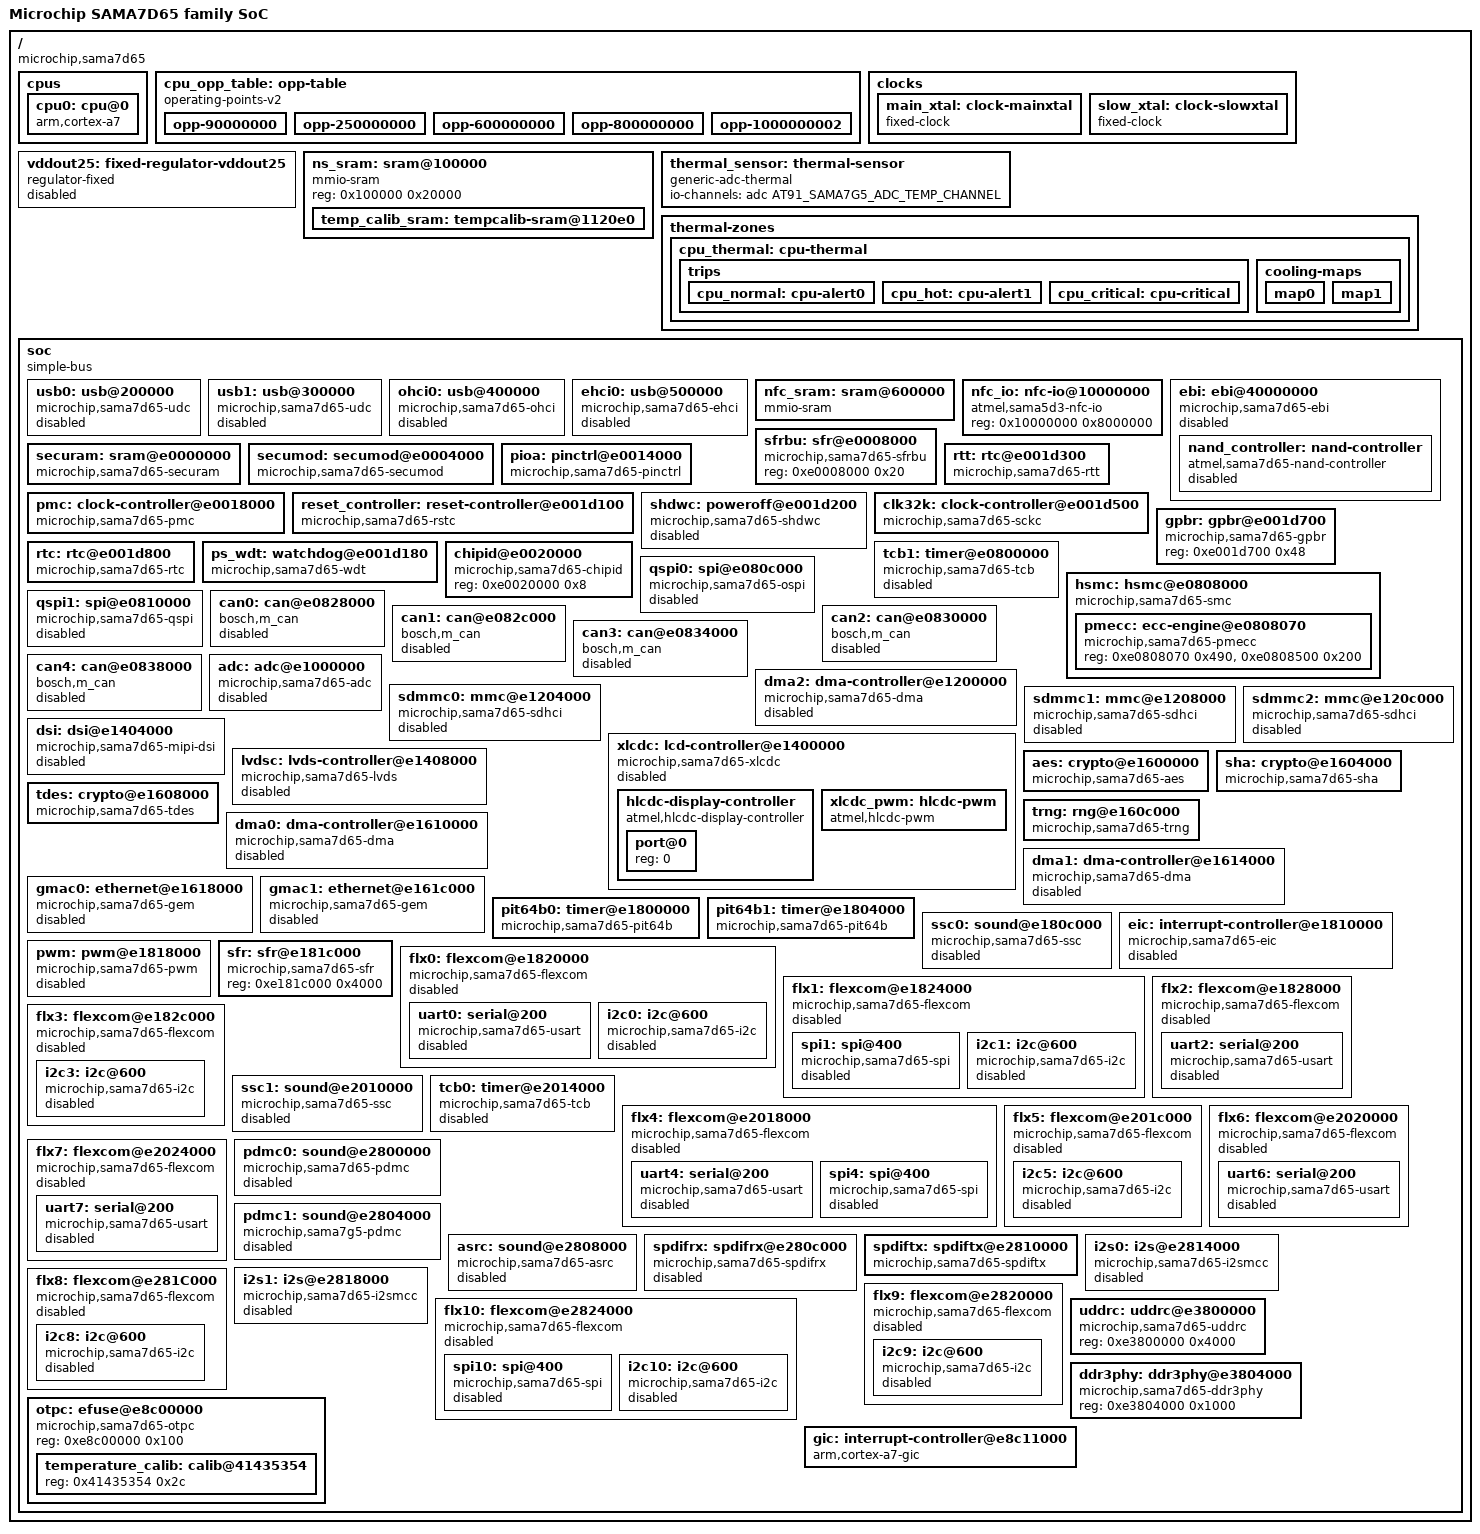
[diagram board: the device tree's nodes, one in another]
// SPDX-License-Identifier: (GPL-2.0+ OR MIT)
/*
 *  sama7d65.dtsi - Device Tree Include file for SAMA7D65 SoC
 *
 *  Copyright (C) 2024 Microchip Technology Inc. and its subsidiaries
 *
 *  Author: Ryan Wanner <Ryan.Wanner@microchip.com>
 *
 */

#include <dt-bindings/clock/at91.h>
#include <dt-bindings/dma/at91.h>
#include <dt-bindings/gpio/gpio.h>
#include <dt-bindings/iio/adc/at91-sama5d2_adc.h>
#include <dt-bindings/interrupt-controller/arm-gic.h>
#include <dt-bindings/interrupt-controller/irq.h>
#include <dt-bindings/mfd/at91-usart.h>
#include <dt-bindings/nvmem/microchip,sama7g5-otpc.h>
#include <dt-bindings/thermal/thermal.h>
#include <dt-bindings/reset/sama7g5-reset.h>

/ {
	model = "Microchip SAMA7D65 family SoC";
	compatible = "microchip,sama7d65";
	#address-cells = <1>;
	#size-cells = <1>;
	interrupt-parent = <&gic>;

	cpus {
		#address-cells = <1>;
		#size-cells = <0>;

		cpu0: cpu@0 {
			compatible = "arm,cortex-a7";
			reg = <0x0>;
			device_type = "cpu";
			clocks = <&pmc PMC_TYPE_CORE PMC_CPUPLL>;
			clock-names = "cpu";
			operating-points-v2 = <&cpu_opp_table>;
			#cooling-cells = <2>; /* min followed by max */
		};
	};

	cpu_opp_table: opp-table {
		compatible = "operating-points-v2";

		opp-90000000 {
			opp-hz = /bits/ 64 <90000000>;
			opp-microvolt = <1050000 1050000 1225000>;
			clock-latency-ns = <320000>;
		};

		opp-250000000 {
			opp-hz = /bits/ 64 <250000000>;
			opp-microvolt = <1050000 1050000 1225000>;
			clock-latency-ns = <320000>;
		};

		opp-600000000 {
			opp-hz = /bits/ 64 <600000000>;
			opp-microvolt = <1050000 1050000 1225000>;
			clock-latency-ns = <320000>;
			opp-suspend;
		};

		opp-800000000 {
			opp-hz = /bits/ 64 <800000000>;
			opp-microvolt = <1150000 1125000 1225000>;
			clock-latency-ns = <320000>;
		};

		opp-1000000002 {
			opp-hz = /bits/ 64 <1000000002>;
			opp-microvolt = <1250000 1225000 1300000>;
			clock-latency-ns = <320000>;
		};
	};

	clocks {
		main_xtal: clock-mainxtal {
			compatible = "fixed-clock";
			#clock-cells = <0>;
		};

		slow_xtal: clock-slowxtal {
			compatible = "fixed-clock";
			#clock-cells = <0>;
		};
	};

	vddout25: fixed-regulator-vddout25 {
		compatible = "regulator-fixed";

		regulator-name = "VDDOUT25";
		regulator-min-microvolt = <2500000>;
		regulator-max-microvolt = <2500000>;
		regulator-boot-on;
		status = "disabled";
	};

	ns_sram: sram@100000 {
		compatible = "mmio-sram";
		#address-cells = <1>;
		#size-cells = <1>;
		reg = <0x100000 0x20000>;
		ranges;

		temp_calib_sram: tempcalib-sram@1120e0 {
			reg = <0x1120e0 0x40>;
			pool;
		};
	};

	thermal_sensor: thermal-sensor {
		compatible = "generic-adc-thermal";
		#thermal-sensor-cells = <0>;
		io-channels = <&adc AT91_SAMA7G5_ADC_TEMP_CHANNEL>;
		io-channel-names = "sensor-channel";
	};

	thermal-zones {
		cpu_thermal: cpu-thermal {
			polling-delay-passive = <1000>;
			polling-delay = <5000>;
			thermal-sensors = <&thermal_sensor>;

			trips {
				cpu_normal: cpu-alert0 {
					temperature = <90000>;
					hysteresis = <0>;
					type = "passive";
				};

				cpu_hot: cpu-alert1 {
					temperature = <95000>;
					hysteresis = <0>;
					type = "passive";
				};

				cpu_critical: cpu-critical {
					temperature = <100000>;
					hysteresis = <0>;
					type = "critical";
				};
			};

			cooling-maps {
				map0 {
					trip = <&cpu_normal>;
					cooling-device = <&cpu0 THERMAL_NO_LIMIT THERMAL_NO_LIMIT>;
				};

				map1 {
					trip = <&cpu_hot>;
					cooling-device = <&cpu0 THERMAL_NO_LIMIT THERMAL_NO_LIMIT>;
				};
			};
		};
	};

	soc {
		compatible = "simple-bus";
		ranges;
		#address-cells = <1>;
		#size-cells = <1>;

		usb0: usb@200000 {		// AT91 USB device controller on port A
			compatible = "microchip,sama7d65-udc", "microchip,sama7g5-udc";
			reg = <0x00200000 0x100000>,
			      <0xe0814000 0x400>;
			#address-cells = <1>;
			#size-cells = <0>;
			interrupts = <GIC_SPI 99 IRQ_TYPE_LEVEL_HIGH>;
			clocks = <&pmc PMC_TYPE_PERIPHERAL 99>, <&pmc PMC_TYPE_CORE PMC_UTMI>;
			clock-names = "pclk", "hclk";
			assigned-clocks = <&pmc PMC_TYPE_CORE PMC_UTMI>;
			assigned-clock-rates = <480000000>;
			status = "disabled";
		};

		usb1: usb@300000 {		// AT91 USB device controller on port B
			compatible = "microchip,sama7d65-udc", "microchip,sama7g5-udc";
			reg = <0x300000 0x100000>,
			      <0xe0818000 0x400>;
			#address-cells = <1>;
			#size-cells = <0>;
			interrupts = <GIC_SPI 100 IRQ_TYPE_LEVEL_HIGH>;
			clocks = <&pmc PMC_TYPE_PERIPHERAL 100>, <&pmc PMC_TYPE_CORE PMC_UTMI>;
			clock-names = "pclk", "hclk";
			assigned-clocks = <&pmc PMC_TYPE_CORE PMC_UTMI>;
			assigned-clock-rates = <480000000>;
			status = "disabled";
		};

		ohci0: usb@400000 {
			compatible = "microchip,sama7d65-ohci", "microchip,sama7g5-ohci", "usb-ohci";
			reg = <0x00400000 0x100000>;
			interrupts = <GIC_SPI 101 IRQ_TYPE_LEVEL_HIGH>;
			clocks = <&pmc PMC_TYPE_PERIPHERAL 101>, <&pmc PMC_TYPE_PERIPHERAL 101>, <&pmc PMC_TYPE_SYSTEM 6> ;
			clock-names = "ohci_clk", "hclk", "uhpck";
			status = "disabled";
		};

		ehci0: usb@500000 {
			compatible = "microchip,sama7d65-ehci", "atmel,at91sam9g45-ehci", "usb-ehci";
			reg = <0x00500000 0x100000>;
			interrupts = <GIC_SPI 101 IRQ_TYPE_LEVEL_HIGH>;
			clocks =<&pmc PMC_TYPE_CORE PMC_UTMI> , <&pmc PMC_TYPE_PERIPHERAL 101>;
			clock-names = "usb_clk", "ehci_clk";
			assigned-clocks = <&pmc PMC_TYPE_CORE PMC_UTMI>;
			assigned-clock-rates = <480000000>;
			status = "disabled";
		};

		nfc_sram: sram@600000 {
			compatible = "mmio-sram";
			no-memory-wc;
			reg = <0x00600000 0x2400>;
			#address-cells = <1>;
			#size-cells = <1>;
			ranges = <0 0x00600000 0x2400>;
		};

		nfc_io: nfc-io@10000000 {
			compatible = "atmel,sama5d3-nfc-io", "syscon";
			reg = <0x10000000 0x8000000>;
		};

		ebi: ebi@40000000 {
			compatible = "microchip,sama7d65-ebi", "atmel,sama5d3-ebi";
			#address-cells = <2>;
			#size-cells = <1>;
			atmel,smc = <&hsmc>;
			reg = <0x40000000 0x18000000>;
			ranges = <0x0 0x0 0x40000000 0x8000000
				  0x1 0x0 0x48000000 0x10000000>;
			clocks = <&pmc PMC_TYPE_CORE PMC_MCK5>; /* PMC_MCK5 */
			status = "disabled";

			nand_controller: nand-controller {
				compatible = "atmel,sama7d65-nand-controller", "atmel,sama5d3-nand-controller";
				atmel,nfc-sram = <&nfc_sram>;
				atmel,nfc-io = <&nfc_io>;
				ecc-engine = <&pmecc>;
				#address-cells = <2>;
				#size-cells = <1>;
				ranges;
				status = "disabled";
			};
		};

		securam: sram@e0000000 {
			compatible = "microchip,sama7d65-securam", "atmel,sama5d2-securam", "mmio-sram";
			reg = <0xe0000000 0x4000>;
			clocks = <&pmc PMC_TYPE_PERIPHERAL 17>;
			#address-cells = <1>;
			#size-cells = <1>;
			ranges = <0 0xe0000000 0x4000>;
			no-memory-wc;
		};

		secumod: secumod@e0004000 {
			compatible = "microchip,sama7d65-secumod", "atmel,sama5d2-secumod", "syscon";
			reg = <0xe0004000 0x4000>;
			gpio-controller;
			#gpio-cells = <2>;
		};

		sfrbu: sfr@e0008000 {
			compatible ="microchip,sama7d65-sfrbu", "atmel,sama5d2-sfrbu", "syscon";
			reg = <0xe0008000 0x20>;
		};

		pioa: pinctrl@e0014000 {
			compatible = "microchip,sama7d65-pinctrl";
			reg = <0xe0014000 0x800>;
			interrupts = <GIC_SPI 10 IRQ_TYPE_LEVEL_HIGH>,
				     <GIC_SPI 11 IRQ_TYPE_LEVEL_HIGH>,
				     <GIC_SPI 12 IRQ_TYPE_LEVEL_HIGH>,
				     <GIC_SPI 13 IRQ_TYPE_LEVEL_HIGH>,
				     <GIC_SPI 14 IRQ_TYPE_LEVEL_HIGH>;
			clocks = <&pmc PMC_TYPE_PERIPHERAL 10>;
			interrupt-controller;
			#interrupt-cells = <2>;
			gpio-controller;
			#gpio-cells = <2>;
		};

		pmc: clock-controller@e0018000 {
			compatible = "microchip,sama7d65-pmc", "syscon";
			reg = <0xe0018000 0x200>;
			interrupts = <GIC_SPI 9 IRQ_TYPE_LEVEL_HIGH>;
			#clock-cells = <2>;
			clocks = <&clk32k 1>, <&clk32k 0>, <&main_xtal>;
			clock-names = "td_slck", "md_slck", "main_xtal";
		};

		reset_controller: reset-controller@e001d100 {
			compatible = "microchip,sama7d65-rstc", "microchip,sama7g5-rstc";
			reg = <0xe001d100 0xc>, <0xe001d1e4 0x4>;
			#reset-cells = <1>;
			clocks = <&clk32k 0>;
		};

		shdwc: poweroff@e001d200 {
			compatible = "microchip,sama7d65-shdwc", "microchip,sama7g5-shdwc", "syscon";
			reg = <0xe001d200 0x20>;
			clocks = <&clk32k 0>;
			#address-cells = <1>;
			#size-cells = <0>;
			atmel,wakeup-rtc-timer;
			atmel,wakeup-rtt-timer;
			status = "disabled";
		};

		rtt: rtc@e001d300 {
			compatible = "microchip,sama7d65-rtt", "microchip,sama7g5-rtt", "microchip,sam9x60-rtt", "atmel,at91sam9260-rtt";
			reg = <0xe001d300 0x30>;
			interrupts = <GIC_SPI 7 IRQ_TYPE_LEVEL_HIGH>;
			clocks = <&clk32k 0>;
		};

		clk32k: clock-controller@e001d500 {
			compatible = "microchip,sama7d65-sckc", "microchip,sam9x60-sckc";
			reg = <0xe001d500 0x4>;
			clocks = <&slow_xtal>;
			#clock-cells = <1>;
		};

		gpbr: gpbr@e001d700 {
			compatible = "microchip,sama7d65-gpbr", "syscon";
			reg = <0xe001d700 0x48>;
		};

		rtc: rtc@e001d800 {
			compatible = "microchip,sama7d65-rtc", "microchip,sama7g5-rtc", "microchip,sam9x60-rtc";
			reg = <0xe001d800 0x30>;
			interrupts = <GIC_SPI 6 IRQ_TYPE_LEVEL_HIGH>;
			clocks = <&clk32k 1>;
		};

		ps_wdt: watchdog@e001d180 {
			compatible = "microchip,sama7d65-wdt", "microchip,sama7g5-wdt";
			reg = <0xe001d000 0x30>;
			interrupts = <GIC_SPI 2 IRQ_TYPE_LEVEL_HIGH>;
			clocks = <&clk32k 0>;
		};

		chipid@e0020000 {
			compatible = "microchip,sama7d65-chipid";
			reg = <0xe0020000 0x8>;
		};

		tcb1: timer@e0800000 {
			compatible = "microchip,sama7d65-tcb", "atmel,sama5d2-tcb", "simple-mfd", "syscon";
			#address-cells = <1>;
			#size-cells = <0>;
			reg = <0xe0800000 0x100>;
			interrupts = <GIC_SPI 86 IRQ_TYPE_LEVEL_HIGH>, <GIC_SPI 87 IRQ_TYPE_LEVEL_HIGH>, <GIC_SPI 88 IRQ_TYPE_LEVEL_HIGH>;
			clocks = <&pmc PMC_TYPE_PERIPHERAL 86>, <&pmc PMC_TYPE_PERIPHERAL 87>,
				 <&pmc PMC_TYPE_PERIPHERAL 88>, <&pmc PMC_TYPE_GCK 86>, <&clk32k 1>;
			clock-names = "t0_clk", "t1_clk", "t2_clk", "gclk", "slow_clk";
			status = "disabled";
		};

		hsmc: hsmc@e0808000 {
			compatible = "microchip,sama7d65-smc", "atmel,sama5d2-smc", "syscon", "simple-mfd";
			reg = <0xe0808000 0x1000>;
			interrupts = <GIC_SPI 20 IRQ_TYPE_LEVEL_HIGH>;
			clocks = <&pmc PMC_TYPE_PERIPHERAL 20>;
			#address-cells = <1>;
			#size-cells = <1>;
			ranges;

			pmecc: ecc-engine@e0808070 {
				compatible = "microchip,sama7d65-pmecc", "atmel,sama5d2-pmecc";
				reg = <0xe0808070 0x490>,
				      <0xe0808500 0x200>;
			};
		};

		qspi0: spi@e080c000 {
			compatible = "microchip,sama7d65-ospi";
			reg = <0xe080c000 0x400>, <0x20000000 0x1000000>;
			reg-names = "qspi_base", "qspi_mmap";
			interrupts = <GIC_SPI 73 IRQ_TYPE_LEVEL_HIGH>;
			dmas = <&dma0 AT91_XDMAC_DT_PERID(41)>,
			       <&dma0 AT91_XDMAC_DT_PERID(40)>;
			dma-names = "tx", "rx";
			clocks = <&pmc PMC_TYPE_PERIPHERAL 73>, <&pmc PMC_TYPE_GCK 73>;
			clock-names = "pclk", "gclk";
			#address-cells = <1>;
			#size-cells = <0>;
			status = "disabled";
		};

		qspi1: spi@e0810000 {
			compatible = "microchip,sama7d65-qspi";
			reg = <0xe0810000 0x400>, <0x30000000 0x1000000>;
			reg-names = "qspi_base", "qspi_mmap";
			interrupts = <GIC_SPI 74 IRQ_TYPE_LEVEL_HIGH>;
			dmas = <&dma0 AT91_XDMAC_DT_PERID(43)>,
			       <&dma0 AT91_XDMAC_DT_PERID(42)>;
			dma-names = "tx", "rx";
			clocks = <&pmc PMC_TYPE_PERIPHERAL 74>, <&pmc PMC_TYPE_GCK 74>;
			clock-names = "pclk", "gclk";
			#address-cells = <1>;
			#size-cells = <0>;
			status = "disabled";
		};

		can0: can@e0828000 {
			compatible = "bosch,m_can";
			reg = <0xe0828000 0x200>, <0x100000 0x7800>;
			reg-names = "m_can", "message_ram";
			interrupts = <GIC_SPI 58 IRQ_TYPE_LEVEL_HIGH>,
				     <GIC_SPI 114 IRQ_TYPE_LEVEL_HIGH>;
			interrupt-names = "int0", "int1";
			clocks = <&pmc PMC_TYPE_PERIPHERAL 58>, <&pmc PMC_TYPE_GCK 58>;
			clock-names = "hclk", "cclk";
			assigned-clocks = <&pmc PMC_TYPE_GCK 58>;
			assigned-clock-rates = <40000000>;
			assigned-clock-parents = <&pmc PMC_TYPE_CORE PMC_UTMI>;
			bosch,mram-cfg = <0x3400 0 0 64 0 0 32 32>;
			status = "disabled";
		};

		can1: can@e082c000 {
			compatible = "bosch,m_can";
			reg = <0xe082c000 0x200>, <0x100000 0xbc00>;
			reg-names = "m_can", "message_ram";
			interrupts = <GIC_SPI 59 IRQ_TYPE_LEVEL_HIGH>,
				     <GIC_SPI 115 IRQ_TYPE_LEVEL_HIGH>;
			interrupt-names = "int0", "int1";
			clocks = <&pmc PMC_TYPE_PERIPHERAL 59>, <&pmc PMC_TYPE_GCK 59>;
			clock-names = "hclk", "cclk";
			assigned-clocks = <&pmc PMC_TYPE_GCK 59>;
			assigned-clock-rates = <40000000>;
			assigned-clock-parents = <&pmc PMC_TYPE_CORE PMC_UTMI>;
			bosch,mram-cfg = <0x7800 0 0 64 0 0 32 32>;
			status = "disabled";
		};

		can2: can@e0830000 {
			compatible = "bosch,m_can";
			reg = <0xe0830000 0x200>, <0x100000 0x10000>;
			reg-names = "m_can", "message_ram";
			interrupts = <GIC_SPI 60 IRQ_TYPE_LEVEL_HIGH>,
				     <GIC_SPI 116 IRQ_TYPE_LEVEL_HIGH>;
			interrupt-names = "int0", "int1";
			clocks = <&pmc PMC_TYPE_PERIPHERAL 60>, <&pmc PMC_TYPE_GCK 60>;
			clock-names = "hclk", "cclk";
			assigned-clocks = <&pmc PMC_TYPE_GCK 60>;
			assigned-clock-rates = <40000000>;
			assigned-clock-parents = <&pmc PMC_TYPE_CORE PMC_UTMI>;
			bosch,mram-cfg = <0xbc00 0 0 64 0 0 32 32>;
			status = "disabled";
		};

		can3: can@e0834000 {
			compatible = "bosch,m_can";
			reg = <0xe0834000 0x200>, <0x110000 0x4400>;
			reg-names = "m_can", "message_ram";
			interrupts = <GIC_SPI 61 IRQ_TYPE_LEVEL_HIGH>,
				     <GIC_SPI 117 IRQ_TYPE_LEVEL_HIGH>;
			interrupt-names = "int0", "int1";
			clocks = <&pmc PMC_TYPE_PERIPHERAL 61>, <&pmc PMC_TYPE_GCK 61>;
			clock-names = "hclk", "cclk";
			assigned-clocks = <&pmc PMC_TYPE_GCK 61>;
			assigned-clock-rates = <40000000>;
			assigned-clock-parents = <&pmc PMC_TYPE_CORE PMC_UTMI>;
			bosch,mram-cfg = <0x0 0 0 64 0 0 32 32>;
			status = "disabled";
		};

		can4: can@e0838000 {
			compatible = "bosch,m_can";
			reg = <0xe0838000 0x200>, <0x110000 0x8800>;
			reg-names = "m_can", "message_ram";
			interrupts = <GIC_SPI 62 IRQ_TYPE_LEVEL_HIGH>,
				     <GIC_SPI 118 IRQ_TYPE_LEVEL_HIGH>;
			interrupt-names = "int0", "int1";
			clocks = <&pmc PMC_TYPE_PERIPHERAL 62>, <&pmc PMC_TYPE_GCK 62>;
			clock-names = "hclk", "cclk";
			assigned-clocks = <&pmc PMC_TYPE_GCK 62>;
			assigned-clock-rates = <40000000>;
			assigned-clock-parents = <&pmc PMC_TYPE_CORE PMC_UTMI>;
			bosch,mram-cfg = <0x4400 0 0 64 0 0 32 32>;
			status = "disabled";
		};

		adc: adc@e1000000 {
			compatible = "microchip,sama7d65-adc", "microchip,sama7g5-adc";
			reg = <0xe1000000 0x200>;
			interrupts = <GIC_SPI 25 IRQ_TYPE_LEVEL_HIGH>;
			clocks = <&pmc PMC_TYPE_GCK 25>;
			assigned-clocks = <&pmc PMC_TYPE_GCK 25>;
			assigned-clock-rates = <100000000>;
			clock-names = "adc_clk";
			dmas = <&dma0 AT91_XDMAC_DT_PERID(0)>;
			dma-names = "rx";
			atmel,min-sample-rate-hz = <200000>;
			atmel,max-sample-rate-hz = <20000000>;
			atmel,trigger-edge-type = <IRQ_TYPE_EDGE_RISING>;
			atmel,startup-time-ms = <4>;
			#io-channel-cells = <1>;
			nvmem-cells = <&temperature_calib>;
			nvmem-cell-names = "temperature_calib";
			sram = <&temp_calib_sram>;
			status = "disabled";
		};

		dma2: dma-controller@e1200000 {
			compatible = "microchip,sama7d65-dma", "microchip,sama7g5-dma";
			reg = <0xe1200000 0x1000>;
			interrupts = <GIC_SPI 111 IRQ_TYPE_LEVEL_HIGH>;
			#dma-cells = <1>;
			clocks = <&pmc PMC_TYPE_PERIPHERAL 23>;
			clock-names = "dma_clk";
			dma-requests = <0>;
			status = "disabled";
		};

		sdmmc0: mmc@e1204000 {
			compatible = "microchip,sama7d65-sdhci", "microchip,sama7g5-sdhci", "microchip,sam9x60-sdhci";
			reg = <0xe1204000 0x400>;
			interrupts = <GIC_SPI 75 IRQ_TYPE_LEVEL_HIGH>;
			clocks = <&pmc PMC_TYPE_PERIPHERAL 75>, <&pmc PMC_TYPE_GCK 75>;
			clock-names = "hclock", "multclk";
			assigned-clock-parents = <&pmc PMC_TYPE_CORE PMC_BAUDPLL>;
			assigned-clocks = <&pmc PMC_TYPE_GCK 75>;
			assigned-clock-rates = <200000000>;
			microchip,sdcal-inverted;
			status = "disabled";
		};

		sdmmc1: mmc@e1208000 {
			compatible = "microchip,sama7d65-sdhci", "microchip,sama7g5-sdhci", "microchip,sam9x60-sdhci";
			reg = <0xe1208000 0x400>;
			interrupts = <GIC_SPI 76 IRQ_TYPE_LEVEL_HIGH>;
			clocks = <&pmc PMC_TYPE_PERIPHERAL 76>, <&pmc PMC_TYPE_GCK 76>;
			clock-names = "hclock", "multclk";
			assigned-clocks = <&pmc PMC_TYPE_GCK 76>;
			assigned-clock-rates = <200000000>;
			assigned-clock-parents = <&pmc PMC_TYPE_CORE PMC_MCK1>;
			microchip,sdcal-inverted;
			status = "disabled";
		};

		sdmmc2: mmc@e120c000 {
			compatible = "microchip,sama7d65-sdhci", "microchip,sama7g5-sdhci", "microchip,sam9x60-sdhci";
			reg = <0xe120c000 0x400>;
			interrupts = <GIC_SPI 77 IRQ_TYPE_LEVEL_HIGH>;
			clocks = <&pmc PMC_TYPE_PERIPHERAL 77>, <&pmc PMC_TYPE_GCK 77>;
			clock-names = "hclock", "multclk";
			assigned-clock-parents = <&pmc PMC_TYPE_CORE PMC_MCK1>;
			assigned-clocks = <&pmc PMC_TYPE_GCK 77>;
			assigned-clock-rates = <200000000>;
			microchip,sdcal-inverted;
			status = "disabled";
		};

		/*
		 * LCDC clock related properties will be defined in board-specific DT since
		 * a clock source differs between the LVDS and MIPI DSI interfaces.
		 */
		xlcdc: lcd-controller@e1400000{
			compatible = "microchip,sama7d65-xlcdc";
			reg = <0xe1400000 0x2000>;
			interrupts = <GIC_SPI 56 IRQ_TYPE_LEVEL_HIGH>;
			status = "disabled";

			hlcdc-display-controller {
				compatible = "atmel,hlcdc-display-controller";
				#address-cells = <1>;
				#size-cells = <0>;

				port@0 {
					#address-cells = <1>;
					#size-cells = <0>;
					reg = <0>;
				};
			};

			xlcdc_pwm: hlcdc-pwm {
				compatible = "atmel,hlcdc-pwm";
				#pwm-cells = <3>;
			};
		};

		dsi: dsi@e1404000{
			compatible = "microchip,sama7d65-mipi-dsi";
			reg = <0xe1404000 0x200>;
			clocks = <&pmc PMC_TYPE_PERIPHERAL 103>, <&pmc PMC_TYPE_GCK 103>;
			clock-names = "pclk", "refclk";
			assigned-clocks = <&pmc PMC_TYPE_GCK 103>;
			assigned-clock-rates = <24000000>;
			status = "disabled";
		};

		lvdsc: lvds-controller@e1408000 {
			compatible = "microchip,sama7d65-lvds";
			reg = <0xe1408000 0x100>;
			interrupts = <GIC_SPI 104 IRQ_TYPE_LEVEL_HIGH>;
			clocks = <&pmc PMC_TYPE_PERIPHERAL 104>;
			clock-names = "pclk";
			#address-cells = <1>;
			#size-cells = <0>;
			status = "disabled";
		};

		aes: crypto@e1600000 {
			compatible = "microchip,sama7d65-aes", "atmel,at91sam9g46-aes";
			reg = <0xe1600000 0x100>;
			interrupts = <GIC_SPI 26 IRQ_TYPE_LEVEL_HIGH>;
			clocks = <&pmc PMC_TYPE_PERIPHERAL 26>;
			clock-names = "aes_clk";
			dmas = <&dma0 AT91_XDMAC_DT_PERID(1)>,
			       <&dma0 AT91_XDMAC_DT_PERID(2)>;
			dma-names = "tx", "rx";
		};

		sha: crypto@e1604000 {
			compatible = "microchip,sama7d65-sha", "atmel,at91sam9g46-sha";
			reg = <0xe1604000 0x100>;
			interrupts = <GIC_SPI 78 IRQ_TYPE_LEVEL_HIGH>;
			clocks = <&pmc PMC_TYPE_PERIPHERAL 78>;
			clock-names = "sha_clk";
			dmas = <&dma0 AT91_XDMAC_DT_PERID(48)>;
			dma-names = "tx";
		};

		tdes: crypto@e1608000 {
			compatible = "microchip,sama7d65-tdes", "atmel,at91sam9g46-tdes";
			reg = <0xe1608000 0x100>;
			interrupts = <GIC_SPI 91 IRQ_TYPE_LEVEL_HIGH>;
			clocks = <&pmc PMC_TYPE_PERIPHERAL 91>;
			clock-names = "tdes_clk";
			dmas = <&dma0 AT91_XDMAC_DT_PERID(54)>,
			       <&dma0 AT91_XDMAC_DT_PERID(53)>;
			dma-names = "tx", "rx";
		};

		trng: rng@e160c000 {
			compatible = "microchip,sama7d65-trng", "microchip,sam9x60-trng";
			reg = <0xe160c000 0x100>;
			interrupts = <GIC_SPI 92 IRQ_TYPE_LEVEL_HIGH>;
			clocks = <&pmc PMC_TYPE_PERIPHERAL 92>;
		};

		dma0: dma-controller@e1610000 {
			compatible = "microchip,sama7d65-dma", "microchip,sama7g5-dma";
			reg = < 0xe1610000 0x1000>;
			interrupts = <GIC_SPI 109 IRQ_TYPE_LEVEL_HIGH>;
			#dma-cells = <1>;
			clocks = <&pmc PMC_TYPE_PERIPHERAL 21>;
			clock-names = "dma_clk";
			status = "disabled";
		};

		dma1: dma-controller@e1614000 {
			compatible = "microchip,sama7d65-dma", "microchip,sama7g5-dma";
			reg = <0xe1614000 0x1000>;
			interrupts = <GIC_SPI 110 IRQ_TYPE_LEVEL_HIGH>;
			#dma-cells = <1>;
			clocks = <&pmc PMC_TYPE_PERIPHERAL 22>;
			clock-names = "dma_clk";
			status = "disabled";
		};

		gmac0: ethernet@e1618000 {
			compatible = "microchip,sama7d65-gem", "microchip,sama7g5-gem";
			reg = <0xe1618000 0x2000>;
			interrupts = <GIC_SPI 46 IRQ_TYPE_LEVEL_HIGH>,
				     <GIC_SPI 144 IRQ_TYPE_LEVEL_HIGH>,
				     <GIC_SPI 145 IRQ_TYPE_LEVEL_HIGH>,
				     <GIC_SPI 146 IRQ_TYPE_LEVEL_HIGH>,
				     <GIC_SPI 147 IRQ_TYPE_LEVEL_HIGH>,
				     <GIC_SPI 148 IRQ_TYPE_LEVEL_HIGH>;
			clocks = <&pmc PMC_TYPE_PERIPHERAL 46>, <&pmc PMC_TYPE_PERIPHERAL 46>, <&pmc PMC_TYPE_GCK 46>, <&pmc PMC_TYPE_GCK 49>;
			clock-names = "pclk", "hclk", "tx_clk", "tsu_clk";
			assigned-clocks = <&pmc PMC_TYPE_GCK 46>, <&pmc PMC_TYPE_GCK 49>;
			assigned-clock-rates = <125000000>, <200000000>;
			status = "disabled";
		};

		gmac1: ethernet@e161c000 {
			compatible = "microchip,sama7d65-gem", "microchip,sama7g5-gem";
			reg = <0xe161c000 0x2000>;
			interrupts = <GIC_SPI 47 IRQ_TYPE_LEVEL_HIGH>,
				     <GIC_SPI 151 IRQ_TYPE_LEVEL_HIGH>,
				     <GIC_SPI 152 IRQ_TYPE_LEVEL_HIGH>,
				     <GIC_SPI 153 IRQ_TYPE_LEVEL_HIGH>,
				     <GIC_SPI 154 IRQ_TYPE_LEVEL_HIGH>,
				     <GIC_SPI 155 IRQ_TYPE_LEVEL_HIGH>;
			clocks = <&pmc PMC_TYPE_PERIPHERAL 47>, <&pmc PMC_TYPE_PERIPHERAL 47>,<&pmc PMC_TYPE_GCK 47>, <&pmc PMC_TYPE_GCK 50>;
			clock-names = "pclk", "hclk", "tx_clk", "tsu_clk";
			assigned-clocks = <&pmc PMC_TYPE_GCK 47>, <&pmc PMC_TYPE_GCK 50>;
			assigned-clock-rates = <125000000>, <200000000>;
			status = "disabled";
		};

		pit64b0: timer@e1800000 {
			compatible = "microchip,sama7d65-pit64b", "microchip,sam9x60-pit64b";
			reg = <0xe1800000 0x100>;
			interrupts = <GIC_SPI 66 IRQ_TYPE_LEVEL_HIGH>;
			clocks = <&pmc PMC_TYPE_PERIPHERAL 66>, <&pmc PMC_TYPE_GCK 66>;
			clock-names = "pclk", "gclk";
		};

		pit64b1: timer@e1804000 {
			compatible = "microchip,sama7d65-pit64b", "microchip,sam9x60-pit64b";
			reg = <0xe1804000 0x100>;
			interrupts = <GIC_SPI 67 IRQ_TYPE_LEVEL_HIGH>;
			clocks = <&pmc PMC_TYPE_PERIPHERAL 67>, <&pmc PMC_TYPE_GCK 67>;
			clock-names = "pclk", "gclk";
		};

		ssc0: sound@e180c000 {
			compatible = "microchip,sama7d65-ssc";
			reg = <0xe180c000 0x1000>;
			#sound-dai-cells = <0>;
			interrupts = <GIC_SPI 81 IRQ_TYPE_LEVEL_HIGH>;
			dmas = <&dma0 AT91_XDMAC_DT_PERID(44)>,
			       <&dma0 AT91_XDMAC_DT_PERID(45)>;
			dma-names = "rx", "tx";
			clocks = <&pmc PMC_TYPE_PERIPHERAL 81>;
			clock-names = "pclk";
			sound-name-prefix = "SSC0";
			status = "disabled";
		};

		eic: interrupt-controller@e1810000 {
			compatible = "microchip,sama7d65-eic", "microchip,sama7g5-eic";
			reg = <0xe1810000 0xec>;
			interrupt-parent = <&gic>;
			interrupt-controller;
			#interrupt-cells = <2>;
			interrupts = <GIC_SPI 142 IRQ_TYPE_LEVEL_HIGH>,
				     <GIC_SPI 143 IRQ_TYPE_LEVEL_HIGH>;
			clocks = <&pmc PMC_TYPE_PERIPHERAL 33>;
			clock-names = "pclk";
			status = "disabled";
		};

		pwm: pwm@e1818000 {
			compatible = "microchip,sama7d65-pwm", "atmel,sama5d2-pwm";
			reg = <0xe1818000 0x500>;
			interrupts = <GIC_SPI 72 IRQ_TYPE_LEVEL_HIGH>;
			#pwm-cells = <3>;
			clocks = <&pmc PMC_TYPE_PERIPHERAL 72>;
			status = "disabled";
		};

		sfr: sfr@e181c000 {
			compatible = "microchip,sama7d65-sfr", "microchip,sam9x60-sfr", "syscon";
			reg = <0xe181c000 0x4000>;
		};

		flx0: flexcom@e1820000 {
			compatible = "microchip,sama7d65-flexcom", "atmel,sama5d2-flexcom";
			reg = <0xe1820000 0x200>;
			clocks = <&pmc PMC_TYPE_PERIPHERAL 34>;
			#address-cells = <1>;
			#size-cells = <1>;
			ranges = <0x0 0xe1820000 0x800>;
			status = "disabled";

			uart0: serial@200 {
				compatible = "microchip,sama7d65-usart", "atmel,at91sam9260-usart";
				reg = <0x200 0x200>;
				atmel,usart-mode = <AT91_USART_MODE_SERIAL>;
				interrupts = <GIC_SPI 34 IRQ_TYPE_LEVEL_HIGH>;
				clocks = <&pmc PMC_TYPE_PERIPHERAL 34>;
				clock-names = "usart";
				dmas = <&dma1 AT91_XDMAC_DT_PERID(6)>,
					<&dma1 AT91_XDMAC_DT_PERID(5)>;
				dma-names = "tx", "rx";
				atmel,use-dma-rx;
				atmel,use-dma-tx;
				status = "disabled";
			};

			i2c0: i2c@600 {
				compatible = "microchip,sama7d65-i2c", "microchip,sam9x60-i2c";
				reg = <0x600 0x200>;
				interrupts = <GIC_SPI 34 IRQ_TYPE_LEVEL_HIGH>;
				#address-cells = <1>;
				#size-cells = <0>;
				clocks = <&pmc PMC_TYPE_PERIPHERAL 34>;
				atmel,fifo-size = <32>;
				dmas = <&dma0 AT91_XDMAC_DT_PERID(6)>,
					<&dma0 AT91_XDMAC_DT_PERID(5)>;
				dma-names = "tx", "rx";
				status = "disabled";
			};
		};

		flx1: flexcom@e1824000 {
			compatible = "microchip,sama7d65-flexcom", "atmel,sama5d2-flexcom";
			reg = <0xe1824000 0x200>;
			clocks = <&pmc PMC_TYPE_PERIPHERAL 35>;
			#address-cells = <1>;
			#size-cells = <1>;
			ranges = <0x0 0xe1824000 0x800>;
			status = "disabled";

			spi1: spi@400 {
				compatible = "microchip,sama7d65-spi", "atmel,at91rm9200-spi";
				reg = <0x400 0x200>;
				interrupts = <GIC_SPI 35 IRQ_TYPE_LEVEL_HIGH>;
				clocks = <&pmc PMC_TYPE_PERIPHERAL 35>;
				clock-names = "spi_clk";
				#address-cells = <1>;
				#size-cells = <0>;
				atmel,fifo-size = <32>;
				dmas = <&dma0 AT91_XDMAC_DT_PERID(8)>,
					<&dma0 AT91_XDMAC_DT_PERID(7)>;
				dma-names = "tx", "rx";
				status = "disabled";
			};

			i2c1: i2c@600 {
				compatible = "microchip,sama7d65-i2c", "microchip,sam9x60-i2c";
				reg = <0x600 0x200>;
				interrupts = <GIC_SPI 35 IRQ_TYPE_LEVEL_HIGH>;
				#address-cells = <1>;
				#size-cells = <0>;
				clocks = <&pmc PMC_TYPE_PERIPHERAL 35>;
				atmel,fifo-size = <32>;
				dmas = <&dma0 AT91_XDMAC_DT_PERID(8)>,
					<&dma0 AT91_XDMAC_DT_PERID(7)>;
				dma-names = "tx", "rx";
				status = "disabled";
			};
		};

		flx2: flexcom@e1828000 {
			compatible = "microchip,sama7d65-flexcom", "atmel,sama5d2-flexcom";
			reg = <0xe1828000 0x200>;
			clocks = <&pmc PMC_TYPE_PERIPHERAL 36>;
			#address-cells = <1>;
			#size-cells = <1>;
			ranges = <0x0 0xe1828000 0x800>;
			status = "disabled";

			uart2: serial@200 {
				compatible = "microchip,sama7d65-usart", "atmel,at91sam9260-usart";
				reg = <0x200 0x200>;
				atmel,usart-mode = <AT91_USART_MODE_SERIAL>;
				interrupts = <GIC_SPI 36 IRQ_TYPE_LEVEL_HIGH>;
				clocks = <&pmc PMC_TYPE_PERIPHERAL 36>;
				clock-names = "usart";
				dmas = <&dma1 AT91_XDMAC_DT_PERID(10)>,
					<&dma1 AT91_XDMAC_DT_PERID(9)>;
				dma-names = "tx", "rx";
				atmel,use-dma-rx;
				atmel,use-dma-tx;
				status = "disabled";
			};
		};

		flx3: flexcom@e182c000 {
			compatible = "microchip,sama7d65-flexcom", "atmel,sama5d2-flexcom";
			reg = <0xe182C000 0x200>;
			clocks = <&pmc PMC_TYPE_PERIPHERAL 37>;
			#address-cells = <1>;
			#size-cells = <1>;
			ranges = <0x0 0xe182c000 0x800>;
			status = "disabled";

			i2c3: i2c@600 {
				compatible = "microchip,sama7d65-i2c", "microchip,sam9x60-i2c";
				reg = <0x600 0x200>;
				interrupts = <GIC_SPI 37 IRQ_TYPE_LEVEL_HIGH>;
				#address-cells = <1>;
				#size-cells = <0>;
				clocks = <&pmc PMC_TYPE_PERIPHERAL 37>;
				atmel,fifo-size = <32>;
				dmas = <&dma0 AT91_XDMAC_DT_PERID(12)>,
						<&dma0 AT91_XDMAC_DT_PERID(11)>;
				dma-names = "tx", "rx";
				status = "disabled";
			};

		};

		ssc1: sound@e2010000 {
			compatible = "microchip,sama7d65-ssc";
			reg = <0xe2010000 0x1000>;
			#sound-dai-cells = <0>;
			interrupts = <GIC_SPI 82 IRQ_TYPE_LEVEL_HIGH>;
			dmas = <&dma0 AT91_XDMAC_DT_PERID(46)>,
			       <&dma0 AT91_XDMAC_DT_PERID(47)>;
			dma-names = "rx", "tx";
			clocks = <&pmc PMC_TYPE_PERIPHERAL 82>;
			clock-names = "pclk";
			sound-name-prefix = "SSC1";
			status = "disabled";
		};

		tcb0: timer@e2014000{
			compatible = "microchip,sama7d65-tcb", "atmel,sama5d2-tcb", "simple-mfd", "syscon";
			#address-cells = <1>;
			#size-cells = <0>;
			reg = <0xe2014000 0x100>;
			interrupts = <GIC_SPI 83 IRQ_TYPE_LEVEL_HIGH>, <GIC_SPI 84 IRQ_TYPE_LEVEL_HIGH>, <GIC_SPI 85 IRQ_TYPE_LEVEL_HIGH>;
			clocks = <&pmc PMC_TYPE_PERIPHERAL 83>, <&pmc PMC_TYPE_PERIPHERAL 84>,
				 <&pmc PMC_TYPE_PERIPHERAL 85>, <&pmc PMC_TYPE_GCK 83>, <&clk32k 1>;
			clock-names = "t0_clk", "t1_clk", "t2_clk", "gclk", "slow_clk";
			status = "disabled";
		};

		flx4: flexcom@e2018000 {
			compatible = "microchip,sama7d65-flexcom", "atmel,sama5d2-flexcom";
			reg = <0xe2018000 0x200>;
			clocks = <&pmc PMC_TYPE_PERIPHERAL 38>;
			#address-cells = <1>;
			#size-cells = <1>;
			ranges = <0x0 0xe2018000 0x800>;
			status = "disabled";

			uart4: serial@200 {
				compatible = "microchip,sama7d65-usart", "atmel,at91sam9260-usart";
				reg = <0x200 0x200>;
				atmel,usart-mode = <AT91_USART_MODE_SERIAL>;
				interrupts = <GIC_SPI 38 IRQ_TYPE_LEVEL_HIGH>;
				clocks = <&pmc PMC_TYPE_PERIPHERAL 38>;
				clock-names = "usart";
				dmas = <&dma1 AT91_XDMAC_DT_PERID(14)>,
					<&dma1 AT91_XDMAC_DT_PERID(13)>;
				dma-names = "tx", "rx";
				atmel,use-dma-rx;
				atmel,use-dma-tx;
				atmel,fifo-size = <16>;
				status = "disabled";
			};

			spi4: spi@400 {
				compatible = "microchip,sama7d65-spi", "atmel,at91rm9200-spi";
				reg = <0x400 0x200>;
				interrupts = <GIC_SPI 38 IRQ_TYPE_LEVEL_HIGH>;
				clocks = <&pmc PMC_TYPE_PERIPHERAL 38>;
				clock-names = "spi_clk";
				#address-cells = <1>;
				#size-cells = <0>;
				atmel,fifo-size = <32>;
				dmas = <&dma0 AT91_XDMAC_DT_PERID(14)>,
					<&dma0 AT91_XDMAC_DT_PERID(13)>;
				dma-names = "tx", "rx";
				status = "disabled";
			};
		};

		flx5: flexcom@e201c000 {
			compatible = "microchip,sama7d65-flexcom", "atmel,sama5d2-flexcom";
			reg = <0xe201c000 0x200>;
			clocks = <&pmc PMC_TYPE_PERIPHERAL 39>;
			#address-cells = <1>;
			#size-cells = <1>;
			ranges = <0x0 0xe201c000 0x800>;
			status = "disabled";

			i2c5: i2c@600 {
				compatible = "microchip,sama7d65-i2c", "microchip,sam9x60-i2c";
				reg = <0x600 0x200>;
				interrupts = <GIC_SPI 39 IRQ_TYPE_LEVEL_HIGH>;
				#address-cells = <1>;
				#size-cells = <0>;
				clocks = <&pmc PMC_TYPE_PERIPHERAL 39>;
				atmel,fifo-size = <32>;
				dmas = <&dma0 AT91_XDMAC_DT_PERID(16)>,
						<&dma0 AT91_XDMAC_DT_PERID(15)>;
				dma-names = "tx", "rx";
				status = "disabled";
			};
		};

		flx6: flexcom@e2020000 {
			compatible = "microchip,sama7d65-flexcom", "atmel,sama5d2-flexcom";
			reg = <0xe2020000 0x200>;
			ranges = <0x0 0xe2020000 0x800>;
			#address-cells = <1>;
			#size-cells = <1>;
			clocks = <&pmc PMC_TYPE_PERIPHERAL 40>;
			status = "disabled";

			uart6: serial@200 {
				compatible = "microchip,sama7d65-usart", "atmel,at91sam9260-usart";
				reg = <0x200 0x200>;
				interrupts = <GIC_SPI 40 IRQ_TYPE_LEVEL_HIGH>;
				clocks = <&pmc PMC_TYPE_PERIPHERAL 40>;
				clock-names = "usart";
				atmel,usart-mode = <AT91_USART_MODE_SERIAL>;
				dmas = <&dma1 AT91_XDMAC_DT_PERID(18)>,
					<&dma1 AT91_XDMAC_DT_PERID(17)>;
				dma-names = "tx", "rx";
				atmel,use-dma-rx;
				atmel,use-dma-tx;
				atmel,fifo-size = <16>;
				status = "disabled";
			};
		};

		flx7: flexcom@e2024000 {
			compatible = "microchip,sama7d65-flexcom", "atmel,sama5d2-flexcom";
			reg = <0xe2024000 0x200>;
			clocks = <&pmc PMC_TYPE_PERIPHERAL 41>;
			#address-cells = <1>;
			#size-cells = <1>;
			ranges = <0x0 0xe2024000 0x800>;
			status = "disabled";

			uart7: serial@200 {
				compatible = "microchip,sama7d65-usart", "atmel,at91sam9260-usart";
				reg = <0x200 0x200>;
				interrupts = <GIC_SPI 41 IRQ_TYPE_LEVEL_HIGH>;
				clocks = <&pmc PMC_TYPE_PERIPHERAL 41>;
				clock-names = "usart";
				dmas = <&dma1 AT91_XDMAC_DT_PERID(20)>,
					<&dma1 AT91_XDMAC_DT_PERID(19)>;
				dma-names = "tx", "rx";
				atmel,use-dma-rx;
				atmel,use-dma-tx;
				atmel,fifo-size = <16>;
				status = "disabled";
			};
		};

		pdmc0: sound@e2800000{
			compatible = "microchip,sama7d65-pdmc";
			reg = <0xe2800000 0x1000>;
			interrupts = <GIC_SPI 64 IRQ_TYPE_LEVEL_HIGH>;
			#sound-dai-cells = <0>;
			dmas = <&dma0 AT91_XDMAC_DT_PERID(37)>;
			dma-names = "rx";
			clocks = <&pmc PMC_TYPE_PERIPHERAL 64>, <&pmc PMC_TYPE_GCK 64>;
			clock-names = "pclk", "gclk";
			sound-name-prefix = "PDMC0";
			status = "disabled";
		};

		pdmc1: sound@e2804000 {
			compatible = "microchip,sama7g5-pdmc";
			reg = <0xe2804000 0x1000>;
			interrupts = <GIC_SPI 65 IRQ_TYPE_LEVEL_HIGH>;
			#sound-dai-cells = <0>;
			dmas = <&dma0 AT91_XDMAC_DT_PERID(38)>;
			dma-names = "rx";
			clocks = <&pmc PMC_TYPE_PERIPHERAL 65>, <&pmc PMC_TYPE_GCK 65>;
			clock-names = "pclk", "gclk";
			sound-name-prefix = "PDMC1";
			status = "disabled";
		};

		asrc: sound@e2808000{
			compatible = "microchip,sama7d65-asrc";
			reg = <0xe2808000 0x1000>;
			interrupts = <GIC_SPI 29 IRQ_TYPE_LEVEL_HIGH>;
			#sound-dai-cells = <1>;
			dmas = <&dma0 AT91_XDMAC_DT_PERID(55)>,
			       <&dma0 AT91_XDMAC_DT_PERID(56)>,
			       <&dma0 AT91_XDMAC_DT_PERID(57)>,
			       <&dma0 AT91_XDMAC_DT_PERID(58)>,
			       <&dma0 AT91_XDMAC_DT_PERID(59)>,
			       <&dma0 AT91_XDMAC_DT_PERID(60)>,
			       <&dma0 AT91_XDMAC_DT_PERID(61)>,
			       <&dma0 AT91_XDMAC_DT_PERID(62)>;
			dma-names = "rx0", "tx0", "rx1", "tx1",
				    "rx2", "tx2", "rx3", "tx3";
			clocks = <&pmc PMC_TYPE_PERIPHERAL 29>, <&pmc PMC_TYPE_GCK 29>;
			clock-names = "pclk", "gclk";
			microchip,triggers = <&i2s0>, <&i2s1>, <&pdmc0>, <&pdmc1>,
					     <&ssc0>, <&ssc1>, <&spdiftx>, <&spdifrx>;
			microchip,trigger-indexes = <1>, <2>, <3>, <4>, <5>, <8>, <9>, <10>;	/* Found from ASRC_TRIG register */
			microchip,direct-path-indexes = <1> , <0>, /* I2SMCC0: TX, RX */		/*Found from ASRC_DAPSELR register */
							<0>, <1>, /* I2SMCC1: TX, RX */
							<3>, <3>, /* PDMC0:   TX, RX */
							<5>, <4>, /* PDMC1:   TX, RX */
							<3>, <5>, /* SSC0:    TX, RX */
							<4>, <6>, /* SSC1:    TX, RX */
							<2>, <2>, /* SPDIFTX: TX */
							<2>, <2>; /* SPDIFRX: RX */
			assigned-clocks = <&pmc PMC_TYPE_GCK 29>;
			assigned-clock-parents = <&pmc PMC_TYPE_CORE PMC_AUDIOPMCPLL>;
			status = "disabled";
		};

		spdifrx: spdifrx@e280c000{
			#sound-dai-cells = <0>;
			compatible = "microchip,sama7d65-spdifrx";
			reg = <0xe280c000 0x4000>;
			interrupts = <GIC_SPI 79 IRQ_TYPE_LEVEL_HIGH>;
			dmas = <&dma0 AT91_XDMAC_DT_PERID(49)>;
			dma-names = "rx";
			clocks = <&pmc PMC_TYPE_PERIPHERAL 79>, <&pmc PMC_TYPE_GCK 79>;
			clock-names = "pclk", "gclk";
			status = "disabled";
			sound-name-prefix = "SPDIFRX0";
		};

		spdiftx: spdiftx@e2810000 {
			#sound-dai-cells = <0>;
			compatible = "microchip,sama7d65-spdiftx";
			reg = <0xe2810000 0x4000>;
			interrupts = <GIC_SPI 80 IRQ_TYPE_LEVEL_HIGH>;
			dmas = <&dma0 AT91_XDMAC_DT_PERID(50)>;
			dma-names = "tx";
			clocks = <&pmc PMC_TYPE_PERIPHERAL 80>, <&pmc PMC_TYPE_GCK 80>;
			clock-names = "pclk", "gclk";
			sound-name-prefix = "SPDIFTX0";
		};

		i2s0: i2s@e2814000 {
			compatible = "microchip,sama7d65-i2smcc";
			#sound-dai-cells = <0>;
			reg = <0xe2814000 0x4000>;
			interrupts = <GIC_SPI 54 IRQ_TYPE_LEVEL_HIGH>;
			dmas = <&dma0 AT91_XDMAC_DT_PERID(34)>, <&dma0 AT91_XDMAC_DT_PERID(33)>;
			dma-names = "tx", "rx";
			clocks = <&pmc PMC_TYPE_PERIPHERAL 54>, <&pmc PMC_TYPE_GCK 54>;
			clock-names = "pclk", "gclk";
			sound-name-prefix = "I2SMCC0";
			status = "disabled";
		};

		i2s1: i2s@e2818000 {
			compatible = "microchip,sama7d65-i2smcc";
			#sound-dai-cells = <0>;
			reg = <0xe2818000 0x4000>;
			interrupts = <GIC_SPI 55 IRQ_TYPE_LEVEL_HIGH>;
			dmas = <&dma0 AT91_XDMAC_DT_PERID(36)>, <&dma0 AT91_XDMAC_DT_PERID(35)>;
			dma-names = "tx", "rx";
			clocks = <&pmc PMC_TYPE_PERIPHERAL 55>, <&pmc PMC_TYPE_GCK 55>;
			clock-names = "pclk", "gclk";
			sound-name-prefix = "I2SMCC1";
			status = "disabled";
		};

		flx8: flexcom@e281C000{
			compatible = "microchip,sama7d65-flexcom", "atmel,sama5d2-flexcom";
			reg = <0xe281C000 0x200>;
			clocks = <&pmc PMC_TYPE_PERIPHERAL 42>;
			#address-cells = <1>;
			#size-cells = <1>;
			ranges = <0x0 0xe281C000 0x800>;
			status = "disabled";

			i2c8: i2c@600 {
				compatible = "microchip,sama7d65-i2c", "microchip,sam9x60-i2c";
				reg = <0x600 0x200>;
				interrupts = <GIC_SPI 42 IRQ_TYPE_LEVEL_HIGH>;
				#address-cells = <1>;
				#size-cells = <0>;
				clocks = <&pmc PMC_TYPE_PERIPHERAL 42>;
				atmel,fifo-size = <32>;
				dmas = <&dma0 AT91_XDMAC_DT_PERID(22)>,
					<&dma0 AT91_XDMAC_DT_PERID(21)>;
				dma-names = "tx", "rx";
				status = "disabled";
			};
		};

		flx9: flexcom@e2820000 {
			compatible = "microchip,sama7d65-flexcom", "atmel,sama5d2-flexcom";
			reg = <0xe2820000 0x200>;
			clocks = <&pmc PMC_TYPE_PERIPHERAL 43>;
			#address-cells = <1>;
			#size-cells = <1>;
			ranges = <0x0 0xe2820000 0x800>;
			status = "disabled";

			i2c9: i2c@600 {
				compatible = "microchip,sama7d65-i2c", "microchip,sam9x60-i2c";
				reg = <0x600 0x200>;
				interrupts = <GIC_SPI 43 IRQ_TYPE_LEVEL_HIGH>;
				#address-cells = <1>;
				#size-cells = <0>;
				clocks = <&pmc PMC_TYPE_PERIPHERAL 43>;
				atmel,fifo-size = <32>;
				dmas = <&dma0 AT91_XDMAC_DT_PERID(24)>,
					<&dma0 AT91_XDMAC_DT_PERID(23)>;
				dma-names = "tx", "rx";
				status = "disabled";
			};
		};

		flx10: flexcom@e2824000 {
			compatible = "microchip,sama7d65-flexcom", "atmel,sama5d2-flexcom";
			reg = <0xe2824000 0x200>;
			clocks = <&pmc PMC_TYPE_PERIPHERAL 44>;
			#address-cells = <1>;
			#size-cells = <1>;
			ranges = <0x0 0xe2824000 0x800>;
			status = "disabled";

			spi10: spi@400 {
				compatible = "microchip,sama7d65-spi", "atmel,at91rm9200-spi";
				reg = <0x400 0x200>;
				interrupts = <GIC_SPI 44 IRQ_TYPE_LEVEL_HIGH>;
				clocks = <&pmc PMC_TYPE_PERIPHERAL 44>;
				clock-names = "spi_clk";
				#address-cells = <1>;
				#size-cells = <0>;
				atmel,fifo-size = <32>;
				dmas = <&dma0 AT91_XDMAC_DT_PERID(25)>,
					    <&dma0 AT91_XDMAC_DT_PERID(26)>;
				dma-names = "tx", "rx";
				status = "disabled";
			};

			i2c10: i2c@600 {
				compatible = "microchip,sama7d65-i2c", "microchip,sam9x60-i2c";
				reg = <0x600 0x200>;
				interrupts = <GIC_SPI 44 IRQ_TYPE_LEVEL_HIGH>;
				#address-cells = <1>;
				#size-cells = <0>;
				clocks = <&pmc PMC_TYPE_PERIPHERAL 44>;
				atmel,fifo-size = <32>;
				dmas = <&dma0 AT91_XDMAC_DT_PERID(26)>,
					<&dma0 AT91_XDMAC_DT_PERID(25)>;
				dma-names = "tx", "rx";
				status = "disabled";
			};
		};

		uddrc: uddrc@e3800000 {
			compatible = "microchip,sama7d65-uddrc", "microchip,sama7g5-uddrc";
			reg = <0xe3800000 0x4000>;
		};

		ddr3phy: ddr3phy@e3804000 {
			compatible = "microchip,sama7d65-ddr3phy", "microchip,sama7g5-ddr3phy";
			reg = <0xe3804000 0x1000>;
		};

		otpc: efuse@e8c00000 {
			compatible = "microchip,sama7d65-otpc", "microchip,sama7g5-otpc", "syscon";
			reg = <0xe8c00000 0x100>;
			#address-cells = <1>;
			#size-cells = <1>;

			temperature_calib: calib@41435354 {
				reg = <0x41435354 0x2c>;	/* Temp calib data packet TAG */
			};
		};

		gic: interrupt-controller@e8c11000 {
			compatible = "arm,cortex-a7-gic";
			reg = <0xe8c11000 0x1000>,
			      <0xe8c12000 0x2000>;
			#interrupt-cells = <3>;
			#address-cells = <0>;
			interrupt-controller;
		};
	};
};
